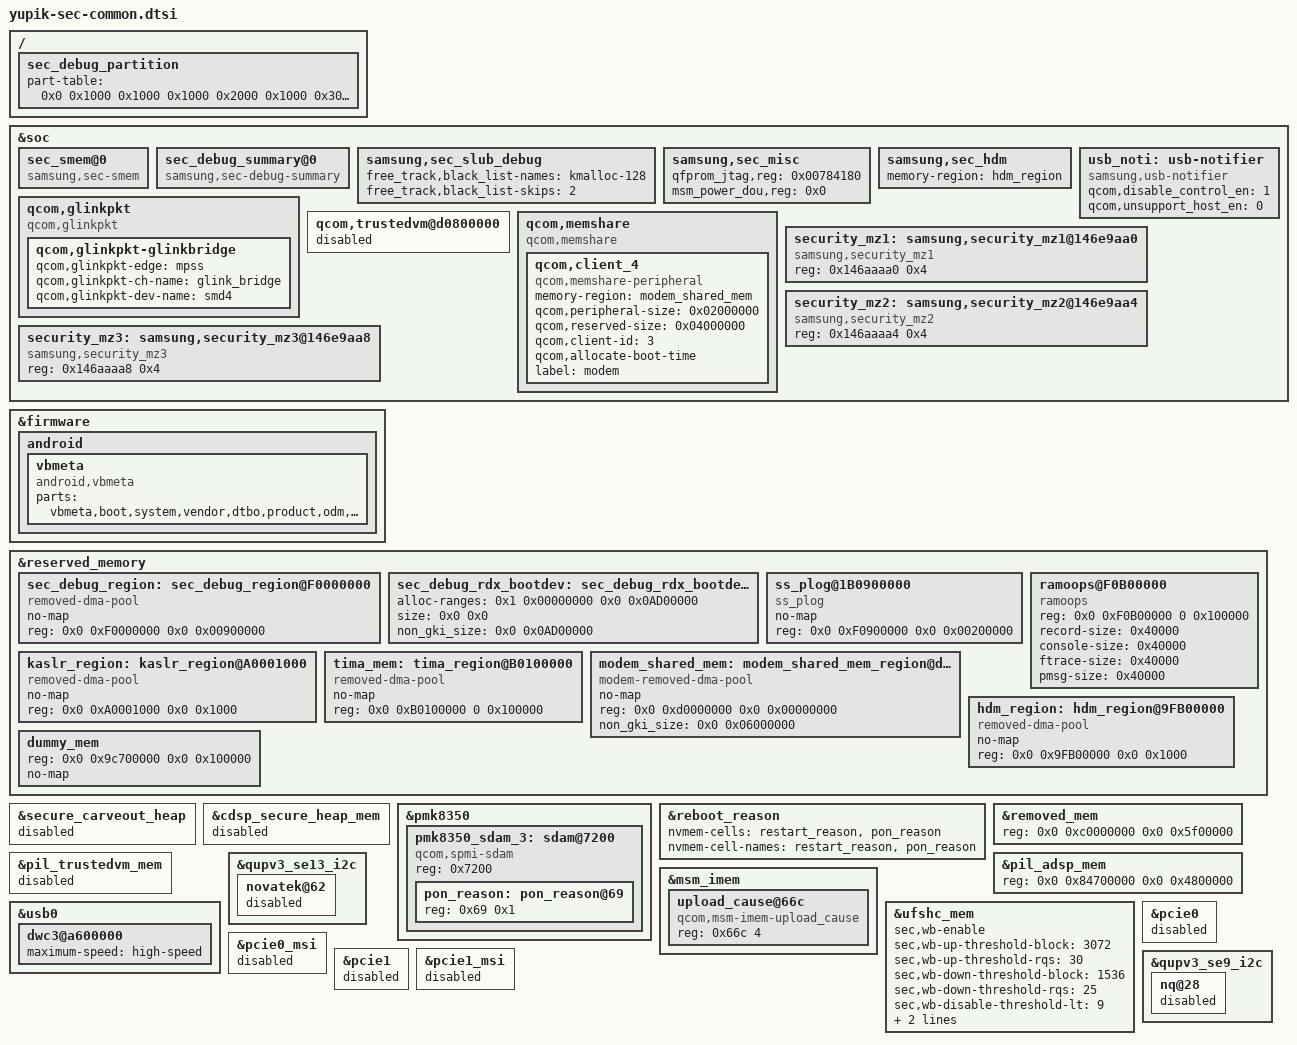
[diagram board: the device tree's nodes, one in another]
/* Copyright (c) 2021, The Linux Foundation. All rights reserved.
 *
 * This program is free software; you can redistribute it and/or modify
 * it under the terms of the GNU General Public License version 2 and
 * only version 2 as published by the Free Software Foundation.
 *
 * This program is distributed in the hope that it will be useful,
 * but WITHOUT ANY WARRANTY; without even the implied warranty of
 * MERCHANTABILITY or FITNESS FOR A PARTICULAR PURPOSE.  See the
 * GNU General Public License for more details.
 */

#include "yupik-sec-pm-common.dtsi"
#include "yupik-sec-uart-common.dtsi"
#include "yupik-sec-dcc-common.dtsi"
#include "yupik-sec-argos-common.dtsi"

&soc {
	sec_smem@0 {
		compatible = "samsung,sec-smem";
		status = "okay";
	};

	sec_debug_summary@0 {
		compatible = "samsung,sec-debug-summary";
		status = "okay";
	};

	samsung,sec_slub_debug {
		free_track,black_list-names = "kmalloc-128";
		free_track,black_list-skips = <2>;
	};

	samsung,sec_misc {
		qfprom_jtag,reg = <0x00784180>;
		msm_power_dou,reg = <0x0>;
	};

	samsung,sec_hdm {
		memory-region = <&hdm_region>;
	};

	usb_noti: usb-notifier {
		compatible = "samsung,usb-notifier";
		qcom,disable_control_en = <1>;
		qcom,unsupport_host_en = <0>;
	};

	qcom,glinkpkt {
		compatible = "qcom,glinkpkt";

		qcom,glinkpkt-glinkbridge {
			qcom,glinkpkt-edge = "mpss";
			qcom,glinkpkt-ch-name = "glink_bridge";
			qcom,glinkpkt-dev-name = "smd4";
		};
	};

	qcom,trustedvm@d0800000 {
		status = "disabled";
	};

	qcom,memshare {
		compatible = "qcom,memshare";

		qcom,client_4 {
			compatible = "qcom,memshare-peripheral";
			memory-region = <&modem_shared_mem>;
			qcom,peripheral-size = <0x02000000>;
			qcom,reserved-size = <0x04000000>;
			qcom,client-id = <3>;
			qcom,allocate-boot-time;
			label = "modem";
		};
	};

	security_mz1: samsung,security_mz1@146e9aa0 {
		compatible = "samsung,security_mz1";
		reg = <0x146aaaa0 0x4>;
	};
	security_mz2: samsung,security_mz2@146e9aa4 {
		compatible = "samsung,security_mz2";
		reg = <0x146aaaa4 0x4>;
	};
	security_mz3: samsung,security_mz3@146e9aa8 {
		compatible = "samsung,security_mz3";
		reg = <0x146aaaa8 0x4>;
	};

};

&firmware {
	android {
		vbmeta {
			compatible = "android,vbmeta";
			parts = "vbmeta,boot,system,vendor,dtbo,product,odm,prism,optics,vbmeta_system,vendor_boot,recovery,abl,xbl,tz,hyp";
		};
	};
};

&reserved_memory {
	/* CONFIG_SEC_DEBUG reserves 9MB */
	sec_debug_region: sec_debug_region@F0000000 {
		compatible = "removed-dma-pool";
		no-map;
		reg = <0x0 0xF0000000 0x0 0x00900000>;
	};

	sec_debug_rdx_bootdev: sec_debug_rdx_bootdev@0 {
		alloc-ranges = <0x1 0x00000000 0x0 0x0AD00000>;
		size = <0x0 0x0>;
		non_gki_size = <0x0 0x0AD00000>;
	};

	ss_plog@1B0900000 {
		compatible = "ss_plog";
		no-map;
		reg = <0x0 0xF0900000 0x0 0x00200000>;
	};

	ramoops@F0B00000 {
		compatible = "ramoops";
		reg = <0x0 0xF0B00000 0 0x100000>;
		record-size = <0x40000>;
		console-size = <0x40000>;
		ftrace-size = <0x40000>;
		pmsg-size = <0x40000>;
	};

	/* Kaslr offset reserve */
	kaslr_region: kaslr_region@A0001000 {
		compatible = "removed-dma-pool";
		no-map;
		reg = <0x0 0xA0001000 0x0 0x1000>;
	};

	/*to reserve 2MB for TIMA */
	tima_mem: tima_region@B0100000 {
		compatible = "removed-dma-pool";
		no-map;
		reg = <0x0 0xB0100000 0 0x100000>;
	};

	modem_shared_mem: modem_shared_mem_region@d0000000 {
		compatible = "modem-removed-dma-pool";
		no-map;
		reg = <0x0 0xd0000000 0x0 0x00000000>;
		non_gki_size = <0x0 0x06000000>;
	};

	hdm_region: hdm_region@9FB00000 {
		compatible = "removed-dma-pool";
		no-map;
		reg = <0x0 0x9FB00000 0x0 0x1000>;
	};

	dummy_mem: dummy_mem {
		reg = <0x0 0x9c700000 0x0 0x100000>;
		no-map;
	};
};

/* disable QC CDSPsec memory region and the related ION heap */
&secure_carveout_heap {
	status = "disabled";
};

&cdsp_secure_heap_mem {
	status = "disabled";
};

&pmk8350 {
	pmk8350_sdam_3: sdam@7200 {
		compatible = "qcom,spmi-sdam";
		reg = <0x7200>;
		#address-cells = <1>;
		#size-cells = <1>;

		pon_reason: pon_reason@69 {
			reg = <0x69 0x1>;
		};
	};
};

&reboot_reason {
	nvmem-cells = <&restart_reason>, <&pon_reason>;
	nvmem-cell-names = "restart_reason", "pon_reason";
};

&removed_mem {
	reg = <0x0 0xc0000000 0x0 0x5f00000>;
};

&pil_trustedvm_mem {
	status = "disabled";
};

&pil_adsp_mem {

    reg = <0x0 0x84700000 0x0 0x4800000>;

};


&msm_imem {
	upload_cause@66c {
		compatible = "qcom,msm-imem-upload_cause";
		reg = <0x66c 4>;
	};
};

&usb0 {
	dwc3@a600000 {
		maximum-speed = "high-speed";
	};
};

&ufshc_mem {
	/* CONFIG_SEC_UFS_WB_FEATURE */
	/* default WB configuration */
	sec,wb-enable;

	/* up threshold for WB on */
	sec,wb-up-threshold-block = <3072>;
	sec,wb-up-threshold-rqs = <30>;

	/* down threshold for WB off */
	sec,wb-down-threshold-block = <1536>;
	sec,wb-down-threshold-rqs = <25>;

	sec,wb-disable-threshold-lt = <9>;

	sec,wb-on-delay-ms = <92>;
	sec,wb-off-delay-ms = <4500>;
};

&qupv3_se13_i2c {
	novatek@62 {
		status = "disabled";
	};
};

&pcie0 {
	status = "disabled";
};

&pcie0_msi {
	status = "disabled";
};

&pcie1 {
	status = "disabled";
};

&pcie1_msi {
	status = "disabled";
};

/ {
	fragment@model {
		target-path = "/";
		__overlay__ {
			sec_debug_partition {
				part-table = <0x0 0x1000
							0x1000 0x1000
							0x2000 0x1000
							0x3000 0x1000
							0x4000 0xA000
							0xE000 0x1000
							0xF000 0x80000
							0x8F000 0x1000
							0x90000 0x3000
							0x93000 0x1000
							0x94000 0x1000
							0x95000 0x1000
							0xFE000 0x2000
							0x100000 0x200000
							0x300000 0x200000
							0x500000 0x300000
							>;
			};
		};
	};
};

&qupv3_se9_i2c {
	nq@28 {
		status = "disabled";
	};
};
